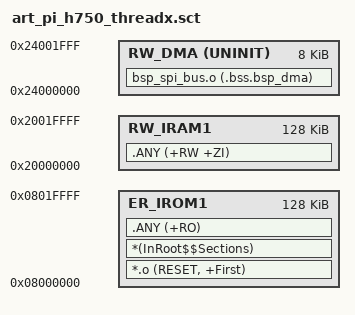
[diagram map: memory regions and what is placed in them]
LR_IROM1 0x08000000 0x00020000
{
    ER_IROM1 0x08000000 0x00020000
    {
        *.o (RESET, +First)
        *(InRoot$$Sections)
        .ANY (+RO)
    }

    RW_IRAM1 0x20000000 0x00020000
    {
        .ANY (+RW +ZI)
    }

    RW_DMA 0x24000000 UNINIT 0x00002000
    {
        bsp_spi_bus.o (.bss.bsp_dma)
    }
}
